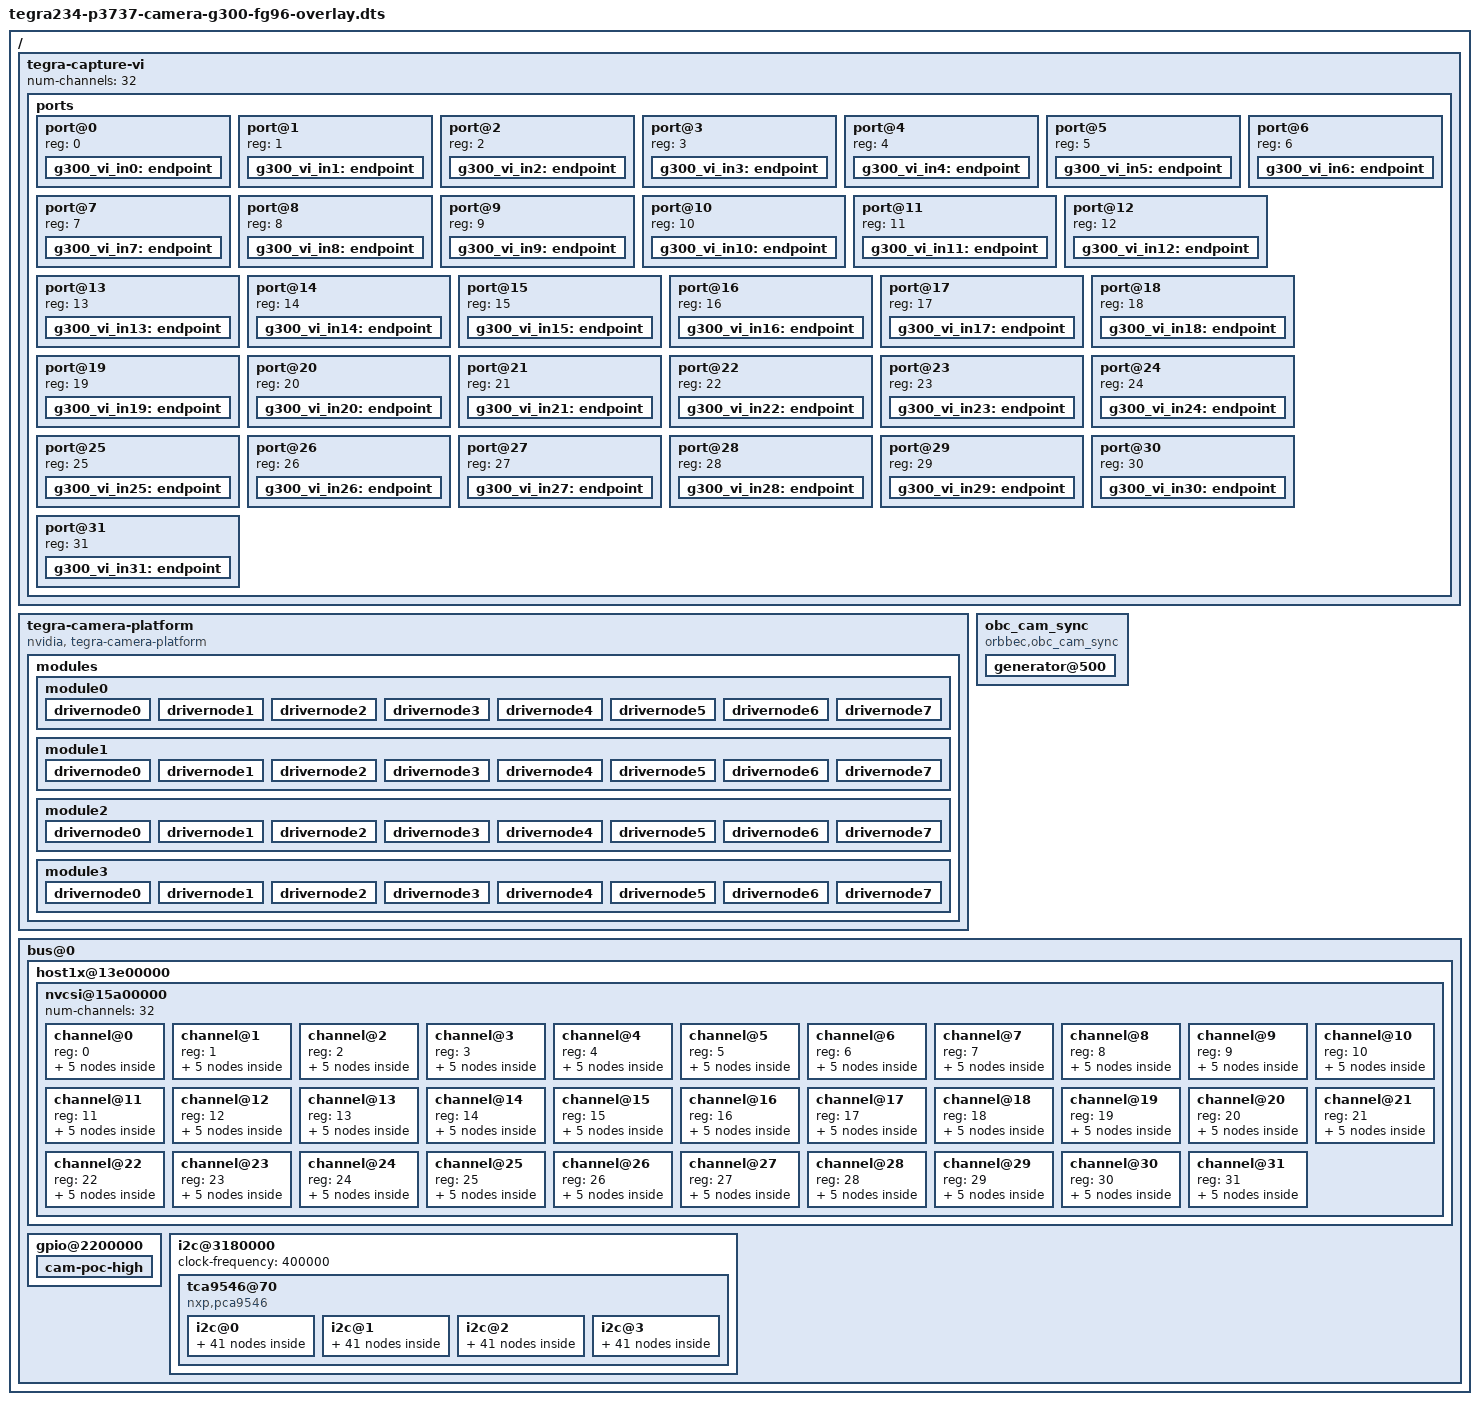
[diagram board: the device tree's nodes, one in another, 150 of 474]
// SPDX-License-Identifier: GPL-2.0-only
// SPDX-FileCopyrightText: Copyright (c) 2024-2029, ORBBEC CORPORATION.  All rights reserved.

/dts-v1/;
/plugin/;

#include <dt-bindings/clock/tegra234-clock.h>
#include <dt-bindings/gpio/tegra234-gpio.h>
#include <dt-bindings/tegra234-p3737-0000+p3701-0000.h>
#include <dt-bindings/pinctrl/pinctrl-tegra.h> 

#define CAM0_PWDN	TEGRA234_MAIN_GPIO(H, 6)  //Pin93 --- UART4_CTS L49/397 - MAX9296_1 PWDN
#define CAM1_PWDN	TEGRA234_MAIN_GPIO(H, 3)  //Pin95 --- UART4_TX L5/394 - MAX9296_2 PWDN
#define CAM2_PWDN	TEGRA234_MAIN_GPIO(AC, 0) //Pin90 --- GPIO15 F10/486 - MAX9296_3 PWDN
#define CAM3_PWDN	TEGRA234_MAIN_GPIO(AC, 1) //Pin92 --- GPIO16 E9/487 - MAX9296_4 PWDN
#define CAM12V_POC	TEGRA234_MAIN_GPIO(AC, 7) //Pin119 --- GPIO12 E10 CAM_VDD_SYS_EN/493 Low enable
#define CAM_SYNCALL	TEGRA234_AON_GPIO(CC, 0)  //E61/SPI2_CLK CAM_INT1/328 -- MAX9296x4 MFP6

#define SYNC_IN    TEGRA234_AON_GPIO(BB, 0) //(BB, 0)

#define PPS_TRIGGER  TEGRA234_AON_GPIO(BB, 2)//(BB, 2)

#define CAMERA_I2C_MUX_BUS(x) (0x1E + x)

/* camera control gpio definitions */
/ {
	overlay-name = "Jetson Orbbec Camera G335Lg";
    jetson-header-name = "Jetson AGX CSI Connector";
    compatible = JETSON_COMPATIBLE;

	fragment@0 {
		target-path = "/";
		__overlay__ {
			tegra-capture-vi {
				num-channels = <32>;
				ports {
					status = "okay";
					#address-cells = <1>;
					#size-cells = <0>;
					port@0 {
						reg = <0>;
						status = "okay";
						g300_vi_in0: endpoint {
							status = "okay";
							vc-id = <0>;
							port-index = <0>; //0
							bus-width = <4>;
							remote-endpoint = <&g300_csi_out0>;
						};
					};
					port@1 {
						reg = <1>;
						status = "okay";
						g300_vi_in1: endpoint {
							status = "okay";
							vc-id = <1>;
							port-index = <0>; //0
							bus-width = <4>;
							remote-endpoint = <&g300_csi_out1>;
						};
					};
					port@2 {
						reg = <2>;
						status = "okay";
						g300_vi_in2: endpoint {
							status = "okay";
							vc-id = <2>;
							port-index = <0>; //0
							bus-width = <4>;
							remote-endpoint = <&g300_csi_out2>;
						};
					};
					port@3 {
						reg = <3>;
						status = "okay";
						g300_vi_in3: endpoint {
							status = "okay";
							vc-id = <3>;
							port-index = <0>; //0
							bus-width = <4>;
							remote-endpoint = <&g300_csi_out3>;
						};
					};

					port@4 {
						reg = <4>;
						status = "okay";
						g300_vi_in4: endpoint {
							status = "okay";
							vc-id = <3>;
							port-index = <0>; //1
							bus-width = <4>;
							remote-endpoint = <&g300_csi_out4>;
						};
					};
					port@5 {
						reg = <5>;
						status = "okay";
						g300_vi_in5: endpoint {
							status = "okay";
							vc-id = <2>;
							port-index = <0>; //1
							bus-width = <4>;
							remote-endpoint = <&g300_csi_out5>;
						};
					};
					port@6 {
						reg = <6>;
						status = "okay";
						g300_vi_in6: endpoint {
							status = "okay";
							vc-id = <1>;
							port-index = <0>; //1
							bus-width = <4>;
							remote-endpoint = <&g300_csi_out6>;
						};
					};
					port@7 {
						reg = <7>;
						status = "okay";
						g300_vi_in7: endpoint {
							status = "okay";
							vc-id = <0>;
							port-index = <0>; //1
							bus-width = <4>;
							remote-endpoint = <&g300_csi_out7>;
						};
					};

					port@8 {
						reg = <8>;
						status = "okay";
						g300_vi_in8: endpoint {
							status = "okay";
							vc-id = <0>;
							port-index = <2>; //2
							bus-width = <4>;
							remote-endpoint = <&g300_csi_out8>;
						};
					};
					port@9 {
						reg = <9>;
						status = "okay";
						g300_vi_in9: endpoint {
							status = "okay";
							vc-id = <1>;
							port-index = <2>; //2
							bus-width = <4>;
							remote-endpoint = <&g300_csi_out9>;
						};
					};
					port@10 {
						reg = <10>;
						status = "okay";
						g300_vi_in10: endpoint {
							status = "okay";
							vc-id = <2>;
							port-index = <2>; //2
							bus-width = <4>;
							remote-endpoint = <&g300_csi_out10>;
						};
					};
					port@11 {
						reg = <11>;
						status = "okay";
						g300_vi_in11: endpoint {
							status = "okay";
							vc-id = <3>;
							port-index = <2>; //2
							bus-width = <4>;
							remote-endpoint = <&g300_csi_out11>;
						};
					};

					port@12 {
						reg = <12>;
						status = "okay";
						g300_vi_in12: endpoint {
							status = "okay";
							vc-id = <3>;
							port-index = <2>; //3
							bus-width = <4>;
							remote-endpoint = <&g300_csi_out12>;
						};
					};
					port@13 {
						reg = <13>;
						status = "okay";
						g300_vi_in13: endpoint {
							status = "okay";
							vc-id = <2>;
							port-index = <2>; //3
							bus-width = <4>;
							remote-endpoint = <&g300_csi_out13>;
						};
					};
					port@14 {
						reg = <14>;
						status = "okay";
						g300_vi_in14: endpoint {
							status = "okay";
							vc-id = <1>;
							port-index = <2>; //3
							bus-width = <4>;
							remote-endpoint = <&g300_csi_out14>;
						};
					};
					port@15 {
						reg = <15>;
						status = "okay";
						g300_vi_in15: endpoint {
							status = "okay";
							vc-id = <0>;
							port-index = <2>; //3
							bus-width = <4>;
							remote-endpoint = <&g300_csi_out15>;
						};
					};

					port@16 {
						reg = <16>;
						status = "okay";
						g300_vi_in16: endpoint {
							status = "okay";
							vc-id = <0>;
							port-index = <4>; //0
							bus-width = <4>;
							remote-endpoint = <&g300_csi_out16>;
						};
					};
					port@17 {
						reg = <17>;
						status = "okay";
						g300_vi_in17: endpoint {
							status = "okay";
							vc-id = <1>;
							port-index = <4>; //0
							bus-width = <4>;
							remote-endpoint = <&g300_csi_out17>;
						};
					};
					port@18 {
						reg = <18>;
						status = "okay";
						g300_vi_in18: endpoint {
							status = "okay";
							vc-id = <2>;
							port-index = <4>; //0
							bus-width = <4>;
							remote-endpoint = <&g300_csi_out18>;
						};
					};
					port@19 {
						reg = <19>;
						status = "okay";
						g300_vi_in19: endpoint {
							status = "okay";
							vc-id = <3>;
							port-index = <4>; //0
							bus-width = <4>;
							remote-endpoint = <&g300_csi_out19>;
						};
					};

					port@20 {
						reg = <20>;
						status = "okay";
						g300_vi_in20: endpoint {
							status = "okay";
							vc-id = <3>;
							port-index = <4>; //1
							bus-width = <4>;
							remote-endpoint = <&g300_csi_out20>;
						};
					};
					port@21 {
						reg = <21>;
						status = "okay";
						g300_vi_in21: endpoint {
							status = "okay";
							vc-id = <2>;
							port-index = <4>; //1
							bus-width = <4>;
							remote-endpoint = <&g300_csi_out21>;
						};
					};
					port@22 {
						reg = <22>;
						status = "okay";
						g300_vi_in22: endpoint {
							status = "okay";
							vc-id = <1>;
							port-index = <4>; //1
							bus-width = <4>;
							remote-endpoint = <&g300_csi_out22>;
						};
					};
					port@23 {
						reg = <23>;
						status = "okay";
						g300_vi_in23: endpoint {
							status = "okay";
							vc-id = <0>;
							port-index = <4>; //1
							bus-width = <4>;
							remote-endpoint = <&g300_csi_out23>;
						};
					};

					port@24 {
						reg = <24>;
						status = "okay";
						g300_vi_in24: endpoint {
							status = "okay";
							vc-id = <0>;
							port-index = <5>; //2
							bus-width = <4>;
							remote-endpoint = <&g300_csi_out24>;
						};
					};
					port@25 {
						reg = <25>;
						status = "okay";
						g300_vi_in25: endpoint {
							status = "okay";
							vc-id = <1>;
							port-index = <5>; //2
							bus-width = <4>;
							remote-endpoint = <&g300_csi_out25>;
						};
					};
					port@26 {
						reg = <26>;
						status = "okay";
						g300_vi_in26: endpoint {
							status = "okay";
							vc-id = <2>;
							port-index = <5>; //2
							bus-width = <4>;
							remote-endpoint = <&g300_csi_out26>;
						};
					};
					port@27 {
						reg = <27>;
						status = "okay";
						g300_vi_in27: endpoint {
							status = "okay";
							vc-id = <3>;
							port-index = <5>; //2
							bus-width = <4>;
							remote-endpoint = <&g300_csi_out27>;
						};
					};

					port@28 {
						reg = <28>;
						status = "okay";
						g300_vi_in28: endpoint {
							status = "okay";
							vc-id = <3>;
							port-index = <5>; //3
							bus-width = <4>;
							remote-endpoint = <&g300_csi_out28>;
						};
					};
					port@29 {
						reg = <29>;
						status = "okay";
						g300_vi_in29: endpoint {
							status = "okay";
							vc-id = <2>;
							port-index = <5>; //3
							bus-width = <4>;
							remote-endpoint = <&g300_csi_out29>;
						};
					};
					port@30 {
						reg = <30>;
						status = "okay";
						g300_vi_in30: endpoint {
							status = "okay";
							vc-id = <1>;
							port-index = <5>; //3
							bus-width = <4>;
							remote-endpoint = <&g300_csi_out30>;
						};
					};
					port@31 {
						reg = <31>;
						status = "okay";
						g300_vi_in31: endpoint {
							status = "okay";
							vc-id = <0>;
							port-index = <5>; //3
							bus-width = <4>;
							remote-endpoint = <&g300_csi_out31>;
						};
					};
				};
			};
			tegra-camera-platform {
				compatible = "nvidia, tegra-camera-platform";
				num_csi_lanes = <16>;
				max_lane_speed = <1500000>;
				min_bits_per_pixel = <8>;
				vi_peak_byte_per_pixel = <2>;
				vi_bw_margin_pct = <25>;
				max_pixel_rate = <750000>;
				isp_peak_byte_per_pixel = <5>;
				isp_bw_margin_pct = <25>;
				status = "okay";

				modules {
					status = "okay";
					module0 {
						status = "okay";
						badge = "g300_0";
						position = "topleft";
						orientation = "1";
						drivernode0 {
							status = "okay";
							/* Declare PCL support driver (classically known as guid)  */
							pcl_id = "v4l2_sensor";
							/* Declare the device-tree hierarchy to driver instance */
							sysfs-device-tree = "/sys/firmware/devicetree/base/bus@0/i2c@3180000/tca9546@70/i2c@0/g2m0@66";
						};

						drivernode1 {
							status = "okay";
							/* Declare PCL support driver (classically known as guid)  */
							pcl_id = "v4l2_sensor";
							/* Declare the device-tree hierarchy to driver instance */
							sysfs-device-tree = "/sys/firmware/devicetree/base/bus@0/i2c@3180000/tca9546@70/i2c@0/g2m1@67";
						};

						drivernode2 {
							status = "okay";
							/* Declare PCL support driver (classically known as guid)  */
							pcl_id = "v4l2_sensor";
							/* Declare the device-tree hierarchy to driver instance */
							sysfs-device-tree = "/sys/firmware/devicetree/base/bus@0/i2c@3180000/tca9546@70/i2c@0/g2m2@68";
						};

						drivernode3 {
							status = "okay";
							/* Declare PCL support driver (classically known as guid)  */
							pcl_id = "v4l2_sensor";
							/* Declare the device-tree hierarchy to driver instance */
							sysfs-device-tree = "/sys/firmware/devicetree/base/bus@0/i2c@3180000/tca9546@70/i2c@0/g2m3@69";
						};

						drivernode4 {
							status = "okay";
							/* Declare PCL support driver (classically known as guid)  */
							pcl_id = "v4l2_sensor";
							/* Declare the device-tree hierarchy to driver instance */
							sysfs-device-tree = "/sys/firmware/devicetree/base/bus@0/i2c@3180000/tca9546@70/i2c@0/g2m0@6A";
						};

						drivernode5 {
							status = "okay";
							/* Declare PCL support driver (classically known as guid)  */
							pcl_id = "v4l2_sensor";
							/* Declare the device-tree hierarchy to driver instance */
							sysfs-device-tree = "/sys/firmware/devicetree/base/bus@0/i2c@3180000/tca9546@70/i2c@0/g2m1@6B";
						};

						drivernode6 {
							status = "okay";
							/* Declare PCL support driver (classically known as guid)  */
							pcl_id = "v4l2_sensor";
							/* Declare the device-tree hierarchy to driver instance */
							sysfs-device-tree = "/sys/firmware/devicetree/base/bus@0/i2c@3180000/tca9546@70/i2c@0/g2m2@6C";
						};

						drivernode7 {
							status = "okay";
							/* Declare PCL support driver (classically known as guid)  */
							pcl_id = "v4l2_sensor";
							/* Declare the device-tree hierarchy to driver instance */
							sysfs-device-tree = "/sys/firmware/devicetree/base/bus@0/i2c@3180000/tca9546@70/i2c@0/g2m3@6D";
						};
					};
					module1 {
						status = "okay";
						badge = "g300_1";
						position = "topright";
						orientation = "1";

						drivernode0 {
							status = "okay";
							/* Declare PCL support driver (classically known as guid)  */
							pcl_id = "v4l2_sensor";
							sysfs-device-tree = "/sys/firmware/devicetree/base/bus@0/i2c@3180000/tca9546@70/i2c@1/g2m0@66";
						};

						drivernode1 {
							status = "okay";
							/* Declare PCL support driver (classically known as guid)  */
							pcl_id = "v4l2_sensor";
							/* Declare the device-tree hierarchy to driver instance */
							sysfs-device-tree = "/sys/firmware/devicetree/base/bus@0/i2c@3180000/tca9546@70/i2c@1/g2m1@67";
						};

						drivernode2 {
							status = "okay";
							/* Declare PCL support driver (classically known as guid)  */
							pcl_id = "v4l2_sensor";
							/* Declare the device-tree hierarchy to driver instance */
							sysfs-device-tree = "/sys/firmware/devicetree/base/bus@0/i2c@3180000/tca9546@70/i2c@1/g2m2@68";
						};

						drivernode3 {
							status = "okay";
							/* Declare PCL support driver (classically known as guid)  */
							pcl_id = "v4l2_sensor";
							/* Declare the device-tree hierarchy to driver instance */
							sysfs-device-tree = "/sys/firmware/devicetree/base/bus@0/i2c@3180000/tca9546@70/i2c@1/g2m3@69";
						};

						drivernode4 {
							status = "okay";
								/* Declare PCL support driver (classically known as guid)  */
							pcl_id = "v4l2_sensor";
							/* Declare the device-tree hierarchy to driver instance */
							sysfs-device-tree = "/sys/firmware/devicetree/base/bus@0/i2c@3180000/tca9546@70/i2c@1/g2m0@6A";
						};

						drivernode5 {
							status = "okay";
							/* Declare PCL support driver (classically known as guid)  */
							pcl_id = "v4l2_sensor";
							/* Declare the device-tree hierarchy to driver instance */
							sysfs-device-tree = "/sys/firmware/devicetree/base/bus@0/i2c@3180000/tca9546@70/i2c@1/g2m1@6B";
						};

						drivernode6 {
							status = "okay";
							/* Declare PCL support driver (classically known as guid)  */
							pcl_id = "v4l2_sensor";
							/* Declare the device-tree hierarchy to driver instance */
							sysfs-device-tree = "/sys/firmware/devicetree/base/bus@0/i2c@3180000/tca9546@70/i2c@1/g2m2@6C";
						};

						drivernode7 {
							status = "okay";
							/* Declare PCL support driver (classically known as guid)  */
							pcl_id = "v4l2_sensor";
							/* Declare the device-tree hierarchy to driver instance */
							sysfs-device-tree = "/sys/firmware/devicetree/base/bus@0/i2c@3180000/tca9546@70/i2c@1/g2m3@6D";
						};
					};

					module2 {
						status = "okay";
						badge = "g300_2";
						position = "bottomleft";
						orientation = "1";

						drivernode0 {
							status = "okay";
							/* Declare PCL support driver (classically known as guid)  */
							pcl_id = "v4l2_sensor";
							sysfs-device-tree = "/sys/firmware/devicetree/base/bus@0/i2c@3180000/tca9546@70/i2c@2/g2m0@66";
						};

						drivernode1 {
							status = "okay";
							/* Declare PCL support driver (classically known as guid)  */
							pcl_id = "v4l2_sensor";
							/* Declare the device-tree hierarchy to driver instance */
							sysfs-device-tree = "/sys/firmware/devicetree/base/bus@0/i2c@3180000/tca9546@70/i2c@2/g2m1@67";
						};

						drivernode2 {
							status = "okay";
							/* Declare PCL support driver (classically known as guid)  */
							pcl_id = "v4l2_sensor";
							/* Declare the device-tree hierarchy to driver instance */
							sysfs-device-tree = "/sys/firmware/devicetree/base/bus@0/i2c@3180000/tca9546@70/i2c@2/g2m2@68";
						};

						drivernode3 {
							status = "okay";
							/* Declare PCL support driver (classically known as guid)  */
							pcl_id = "v4l2_sensor";
							/* Declare the device-tree hierarchy to driver instance */
							sysfs-device-tree = "/sys/firmware/devicetree/base/bus@0/i2c@3180000/tca9546@70/i2c@2/g2m3@69";
						};

						drivernode4 {
							status = "okay";
								/* Declare PCL support driver (classically known as guid)  */
							pcl_id = "v4l2_sensor";
							/* Declare the device-tree hierarchy to driver instance */
							sysfs-device-tree = "/sys/firmware/devicetree/base/bus@0/i2c@3180000/tca9546@70/i2c@2/g2m0@6A";
						};

						drivernode5 {
							status = "okay";
							/* Declare PCL support driver (classically known as guid)  */
							pcl_id = "v4l2_sensor";
							/* Declare the device-tree hierarchy to driver instance */
							sysfs-device-tree = "/sys/firmware/devicetree/base/bus@0/i2c@3180000/tca9546@70/i2c@2/g2m1@6B";
						};

						drivernode6 {
							status = "okay";
							/* Declare PCL support driver (classically known as guid)  */
							pcl_id = "v4l2_sensor";
							/* Declare the device-tree hierarchy to driver instance */
							sysfs-device-tree = "/sys/firmware/devicetree/base/bus@0/i2c@3180000/tca9546@70/i2c@2/g2m2@6C";
						};

						drivernode7 {
							status = "okay";
							/* Declare PCL support driver (classically known as guid)  */
							pcl_id = "v4l2_sensor";
							/* Declare the device-tree hierarchy to driver instance */
							sysfs-device-tree = "/sys/firmware/devicetree/base/bus@0/i2c@3180000/tca9546@70/i2c@2/g2m3@6D";
						};
					};
					module3 {
						status = "okay";
						badge = "g300_3";
						position = "bottomright";
						orientation = "1";

						drivernode0 {
							status = "okay";
							/* Declare PCL support driver (classically known as guid)  */
							pcl_id = "v4l2_sensor";
							sysfs-device-tree = "/sys/firmware/devicetree/base/bus@0/i2c@3180000/tca9546@70/i2c@3/g2m0@66";
						};

						drivernode1 {
							status = "okay";
							/* Declare PCL support driver (classically known as guid)  */
							pcl_id = "v4l2_sensor";
							/* Declare the device-tree hierarchy to driver instance */
							sysfs-device-tree = "/sys/firmware/devicetree/base/bus@0/i2c@3180000/tca9546@70/i2c@3/g2m1@67";
						};

						drivernode2 {
							status = "okay";
							/* Declare PCL support driver (classically known as guid)  */
							pcl_id = "v4l2_sensor";
							/* Declare the device-tree hierarchy to driver instance */
							sysfs-device-tree = "/sys/firmware/devicetree/base/bus@0/i2c@3180000/tca9546@70/i2c@3/g2m2@68";
						};

						drivernode3 {
							status = "okay";
							/* Declare PCL support driver (classically known as guid)  */
							pcl_id = "v4l2_sensor";
							/* Declare the device-tree hierarchy to driver instance */
							sysfs-device-tree = "/sys/firmware/devicetree/base/bus@0/i2c@3180000/tca9546@70/i2c@3/g2m3@69";
						};

						drivernode4 {
							status = "okay";
								/* Declare PCL support driver (classically known as guid)  */
							pcl_id = "v4l2_sensor";
							/* Declare the device-tree hierarchy to driver instance */
							sysfs-device-tree = "/sys/firmware/devicetree/base/bus@0/i2c@3180000/tca9546@70/i2c@3/g2m0@6A";
						};

						drivernode5 {
							status = "okay";
							/* Declare PCL support driver (classically known as guid)  */
							pcl_id = "v4l2_sensor";
							/* Declare the device-tree hierarchy to driver instance */
							sysfs-device-tree = "/sys/firmware/devicetree/base/bus@0/i2c@3180000/tca9546@70/i2c@3/g2m1@6B";
						};

						drivernode6 {
							status = "okay";
							/* Declare PCL support driver (classically known as guid)  */
							pcl_id = "v4l2_sensor";
							/* Declare the device-tree hierarchy to driver instance */
							sysfs-device-tree = "/sys/firmware/devicetree/base/bus@0/i2c@3180000/tca9546@70/i2c@3/g2m2@6C";
						};

						drivernode7 {
							status = "okay";
							/* Declare PCL support driver (classically known as guid)  */
							pcl_id = "v4l2_sensor";
							/* Declare the device-tree hierarchy to driver instance */
							sysfs-device-tree = "/sys/firmware/devicetree/base/bus@0/i2c@3180000/tca9546@70/i2c@3/g2m3@6D";
						};
					};
				};
			};

			obc_cam_sync {
				compatible = "orbbec,obc_cam_sync";
				ranges = <0x0 0x0 0xc6a0000 0x10000>;
				reg = <0x0 0xc6a0000 0x0 0x18>;
				#address-cells = <1>;
				#size-cells = <1>;
				status = "okay";
				//sync-in-gpios = <&gpio_aon SYNC_IN GPIO_ACTIVE_HIGH>;
				//sync-out-gpios = <&gpio_aon CAM_SYNCALL GPIO_ACTIVE_HIGH>;  //Use hrtimer to generate trigger signals
				pwms = <&pwm8 0 33333333>; //Use PWM to generate trigger signals, Default PWM mode, if use hrtimer comment out this line
				/* EDGE_OUT #3 */
				generator@500 {
					reg = <0x500 0x80>;
					freq_hz = <30>;
					duty_cycle = <10>;
					offset_ms = <0>;
					status = "okay";
				};
			};

			bus@0 {
				host1x@13e00000 {
					nvcsi@15a00000 {
						#address-cells = <1>;
						#size-cells = <0>;

						num-channels = <32>;

						channel@0 {
							reg = <0>;
							status = "okay";
							ports {
								status = "okay";
								#address-cells = <1>;
								#size-cells = <0>;
								port@0 {
									reg = <0>;
									status = "okay";
									g300_csi_in0: endpoint@0 {
										status = "okay";
										port-index = <0>; //0
										bus-width = <4>;
										remote-endpoint = <&g2m0_0_out>;
									};
								};
								port@1 {
									reg = <1>;
									status = "okay";
									g300_csi_out0: endpoint@1 {
										status = "okay";
										remote-endpoint = <&g300_vi_in0>;
									};
								};
							};
						};
						channel@1 {
							reg = <1>;
							status = "okay";
							ports {
								status = "okay";
								#address-cells = <1>;
								#size-cells = <0>;
								port@0 {
									reg = <0>;
									status = "okay";
									g300_csi_in1: endpoint@2 {
										status = "okay";
										port-index = <0>; //0
										bus-width = <4>;
										remote-endpoint = <&g2m0_1_out>;
									};
								};
								port@1 {
									reg = <1>;
									status = "okay";
									g300_csi_out1: endpoint@3 {
										status = "okay";
										remote-endpoint = <&g300_vi_in1>;
									};
								};
							};
						};
						channel@2 {
							reg = <2>;
							status = "okay";
							ports {
								status = "okay";
								#address-cells = <1>;
								#size-cells = <0>;
								port@0 {
									reg = <0>;
									status = "okay";
									g300_csi_in2: endpoint@4 {
										status = "okay";
										port-index = <0>; //0
										bus-width = <4>;
										remote-endpoint = <&g2m0_2_out>;
									};
								};
								port@1 {
									reg = <1>;
									status = "okay";
									g300_csi_out2: endpoint@5 {
										status = "okay";
										remote-endpoint = <&g300_vi_in2>;
									};
								};
							};
						};
						channel@3 {
							reg = <3>;
							status = "okay";
							ports {
								status = "okay";
								#address-cells = <1>;
								#size-cells = <0>;
								port@0 {
									reg = <0>;
									status = "okay";
									g300_csi_in3: endpoint@6 {
										status = "okay";
										port-index = <0>; //0
										bus-width = <4>;
										remote-endpoint = <&g2m0_3_out>;
									};
								};
								port@1 {
									reg = <1>;
									status = "okay";
									g300_csi_out3: endpoint@7 {
										status = "okay";
										remote-endpoint = <&g300_vi_in3>;
									};
								};
							};
						};

						channel@4 {
							reg = <4>;
							status = "okay";
							ports {
								status = "okay";
								#address-cells = <1>;
								#size-cells = <0>;
								port@0 {
									reg = <0>;
									status = "okay";
									g300_csi_in4: endpoint@8 {
										status = "okay";
										port-index = <0>; //1
										bus-width = <4>;
										remote-endpoint = <&g2m1_0_out>;
									};
								};
								port@1 {
									reg = <1>;
									status = "okay";
									g300_csi_out4: endpoint@9 {
										status = "okay";
										remote-endpoint = <&g300_vi_in4>;
									};
								};
							};
						};
						channel@5 {
							reg = <5>;
							status = "okay";
							ports {
								status = "okay";
								#address-cells = <1>;
								#size-cells = <0>;
								port@0 {
									reg = <0>;
									status = "okay";
									g300_csi_in5: endpoint@10 {
										status = "okay";
										port-index = <0>; //1
										bus-width = <4>;
										remote-endpoint = <&g2m1_1_out>;
									};
								};
								port@1 {
									reg = <1>;
									status = "okay";
									g300_csi_out5: endpoint@11 {
										status = "okay";
										remote-endpoint = <&g300_vi_in5>;
									};
								};
							};
						};
						channel@6 {
							reg = <6>;
							status = "okay";
							ports {
								status = "okay";
								#address-cells = <1>;
								#size-cells = <0>;
								port@0 {
									reg = <0>;
									status = "okay";
									g300_csi_in6: endpoint@12 {
										status = "okay";
										port-index = <0>; //1
										bus-width = <4>;
										remote-endpoint = <&g2m1_2_out>;
									};
								};
								port@1 {
									reg = <1>;
									status = "okay";
									g300_csi_out6: endpoint@13 {
										status = "okay";
										remote-endpoint = <&g300_vi_in6>;
									};
								};
							};
						};
						channel@7 {
							reg = <7>;
							status = "okay";
							ports {
								status = "okay";
								#address-cells = <1>;
								#size-cells = <0>;
								port@0 {
									reg = <0>;
									status = "okay";
									g300_csi_in7: endpoint@14 {
										status = "okay";
										port-index = <0>; //1
										bus-width = <4>;
										remote-endpoint = <&g2m1_3_out>;
									};
								};
								port@1 {
									reg = <1>;
									status = "okay";
									g300_csi_out7: endpoint@15 {
										status = "okay";
										remote-endpoint = <&g300_vi_in7>;
									};
								};
							};
						};

						channel@8 {
							reg = <8>;
							status = "okay";
							ports {
								status = "okay";
								#address-cells = <1>;
								#size-cells = <0>;
								port@0 {
									reg = <0>;
									status = "okay";
									g300_csi_in8: endpoint@16 {
										status = "okay";
										port-index = <2>; //2
										bus-width = <4>;
										remote-endpoint = <&g2m2_0_out>;
									};
								};
								port@1 {
									reg = <1>;
									status = "okay";
									g300_csi_out8: endpoint@17 {
										status = "okay";
										remote-endpoint = <&g300_vi_in8>;
									};
								};
							};
						};
						channel@9 {
							reg = <9>;
							status = "okay";
							ports {
								status = "okay";
								#address-cells = <1>;
								#size-cells = <0>;
								port@0 {
									reg = <0>;
									status = "okay";
									g300_csi_in9: endpoint@18 {
										status = "okay";
										port-index = <2>; //2
										bus-width = <4>;
										remote-endpoint = <&g2m2_1_out>;
									};
								};
								port@1 {
									reg = <1>;
									status = "okay";
									g300_csi_out9: endpoint@19 {
										status = "okay";
										remote-endpoint = <&g300_vi_in9>;
									};
								};
							};
						};
						channel@10 {
							reg = <10>;
							status = "okay";
							ports {
								status = "okay";
								#address-cells = <1>;
								#size-cells = <0>;
								port@0 {
									reg = <0>;
									status = "okay";
									g300_csi_in10: endpoint@20 {
										status = "okay";
										port-index = <2>; //2
										bus-width = <4>;
										remote-endpoint = <&g2m2_2_out>;
									};
								};
								port@1 {
									reg = <1>;
									status = "okay";
									g300_csi_out10: endpoint@21 {
										status = "okay";
										remote-endpoint = <&g300_vi_in10>;
									};
								};
							};
						};
						channel@11 {
							reg = <11>;
							status = "okay";
							ports {
								status = "okay";
								#address-cells = <1>;
								#size-cells = <0>;
								port@0 {
									reg = <0>;
									status = "okay";
									g300_csi_in11: endpoint@22 {
										status = "okay";
										port-index = <2>; //2
										bus-width = <4>;
										remote-endpoint = <&g2m2_3_out>;
									};
								};
								port@1 {
									reg = <1>;
									status = "okay";
									g300_csi_out11: endpoint@23 {
										status = "okay";
										remote-endpoint = <&g300_vi_in11>;
									};
								};
							};
						};

						channel@12 {
							reg = <12>;
							status = "okay";
							ports {
								status = "okay";
								#address-cells = <1>;
								#size-cells = <0>;
								port@0 {
									reg = <0>;
									status = "okay";
									g300_csi_in12: endpoint@24 {
										status = "okay";
										port-index = <2>; //3
										bus-width = <4>;
										remote-endpoint = <&g2m3_0_out>;
									};
								};
								port@1 {
									reg = <1>;
									status = "okay";
									g300_csi_out12: endpoint@25 {
										status = "okay";
										remote-endpoint = <&g300_vi_in12>;
									};
								};
							};
						};
						channel@13 {
							reg = <13>;
							status = "okay";
							ports {
								status = "okay";
								#address-cells = <1>;
								#size-cells = <0>;
								port@0 {
									reg = <0>;
									status = "okay";
									g300_csi_in13: endpoint@26 {
										status = "okay";
										port-index = <2>; //3
										bus-width = <4>;
										remote-endpoint = <&g2m3_1_out>;
									};
								};
								port@1 {
									reg = <1>;
									status = "okay";
									g300_csi_out13: endpoint@27 {
										status = "okay";
										remote-endpoint = <&g300_vi_in13>;
									};
								};
							};
						};
						channel@14 {
							reg = <14>;
							status = "okay";
							ports {
								status = "okay";
								#address-cells = <1>;
								#size-cells = <0>;
								port@0 {
									reg = <0>;
									status = "okay";
									g300_csi_in14: endpoint@28 {
										status = "okay";
										port-index = <2>; //3
										bus-width = <4>;
										remote-endpoint = <&g2m3_2_out>;
									};
								};
								port@1 {
									reg = <1>;
									status = "okay";
									g300_csi_out14: endpoint@29 {
										status = "okay";
										remote-endpoint = <&g300_vi_in14>;
									};
								};
							};
						};
						channel@15 {
							reg = <15>;
							status = "okay";
							ports {
								status = "okay";
								#address-cells = <1>;
								#size-cells = <0>;
								port@0 {
									reg = <0>;
									status = "okay";
									g300_csi_in15: endpoint@30 {
										status = "okay";
										port-index = <2>; //3
										bus-width = <4>;
										remote-endpoint = <&g2m3_3_out>;
									};
								};
								port@1 {
									reg = <1>;
									status = "okay";
									g300_csi_out15: endpoint@31 {
										status = "okay";
										remote-endpoint = <&g300_vi_in15>;
									};
								};
							};
						};

						channel@16 {
							reg = <16>;
							status = "okay";
							ports {
								status = "okay";
								#address-cells = <1>;
								#size-cells = <0>;
								port@0 {
									reg = <0>;
									status = "okay";
									g300_csi_in16: endpoint@32 {
										status = "okay";
										port-index = <4>; //0
										bus-width = <4>;
										remote-endpoint = <&g2m4_0_out>;
									};
								};
								port@1 {
									reg = <1>;
									status = "okay";
									g300_csi_out16: endpoint@33 {
										status = "okay";
										remote-endpoint = <&g300_vi_in16>;
									};
								};
							};
						};
						channel@17 {
							reg = <17>;
							status = "okay";
							ports {
								status = "okay";
								#address-cells = <1>;
								#size-cells = <0>;
								port@0 {
									reg = <0>;
									status = "okay";
									g300_csi_in17: endpoint@34 {
										status = "okay";
										port-index = <4>; //0
										bus-width = <4>;
										remote-endpoint = <&g2m4_1_out>;
									};
								};
								port@1 {
									reg = <1>;
									status = "okay";
									g300_csi_out17: endpoint@35 {
										status = "okay";
										remote-endpoint = <&g300_vi_in17>;
									};
								};
							};
						};
						channel@18 {
							reg = <18>;
							status = "okay";
							ports {
								status = "okay";
								#address-cells = <1>;
								#size-cells = <0>;
								port@0 {
									reg = <0>;
									status = "okay";
									g300_csi_in18: endpoint@36 {
										status = "okay";
										port-index = <4>; //0
										bus-width = <4>;
										remote-endpoint = <&g2m4_2_out>;
									};
								};
								port@1 {
									reg = <1>;
									status = "okay";
									g300_csi_out18: endpoint@37 {
										status = "okay";
										remote-endpoint = <&g300_vi_in18>;
									};
								};
							};
						};
						channel@19 {
							reg = <19>;
							status = "okay";
							ports {
								status = "okay";
								#address-cells = <1>;
								#size-cells = <0>;
								port@0 {
									reg = <0>;
									status = "okay";
									g300_csi_in19: endpoint@38 {
										status = "okay";
										port-index = <4>; //0
										bus-width = <4>;
										remote-endpoint = <&g2m4_3_out>;
									};
								};
								port@1 {
									reg = <1>;
									status = "okay";
									g300_csi_out19: endpoint@39 {
										status = "okay";
										remote-endpoint = <&g300_vi_in19>;
									};
								};
							};
						};

						channel@20 {
							reg = <20>;
							status = "okay";
							ports {
								status = "okay";
								#address-cells = <1>;
								#size-cells = <0>;
								port@0 {
									reg = <0>;
									status = "okay";
									g300_csi_in20: endpoint@40 {
										status = "okay";
										port-index = <4>; //1
										bus-width = <4>;
										remote-endpoint = <&g2m5_0_out>;
									};
								};
								port@1 {
									reg = <1>;
									status = "okay";
									g300_csi_out20: endpoint@41 {
										status = "okay";
										remote-endpoint = <&g300_vi_in20>;
									};
								};
							};
						};
						channel@21 {
							reg = <21>;
							status = "okay";
							ports {
								status = "okay";
								#address-cells = <1>;
								#size-cells = <0>;
								port@0 {
									reg = <0>;
									status = "okay";
									g300_csi_in21: endpoint@42 {
										status = "okay";
										port-index = <4>; //1
										bus-width = <4>;
										remote-endpoint = <&g2m5_1_out>;
									};
								};
								port@1 {
									reg = <1>;
									status = "okay";
									g300_csi_out21: endpoint@43 {
										status = "okay";
										remote-endpoint = <&g300_vi_in21>;
									};
								};
							};
						};
						channel@22 {
							reg = <22>;
							status = "okay";
							ports {
								status = "okay";
								#address-cells = <1>;
								#size-cells = <0>;
								port@0 {
									reg = <0>;
									status = "okay";
									g300_csi_in22: endpoint@44 {
										status = "okay";
										port-index = <4>; //1
										bus-width = <4>;
										remote-endpoint = <&g2m5_2_out>;
									};
								};
								port@1 {
									reg = <1>;
									status = "okay";
									g300_csi_out22: endpoint@45 {
										status = "okay";
										remote-endpoint = <&g300_vi_in22>;
									};
								};
							};
						};
						channel@23 {
							reg = <23>;
							status = "okay";
							ports {
								status = "okay";
								#address-cells = <1>;
								#size-cells = <0>;
								port@0 {
									reg = <0>;
									status = "okay";
									g300_csi_in23: endpoint@46 {
										status = "okay";
										port-index = <4>; //1
										bus-width = <4>;
										remote-endpoint = <&g2m5_3_out>;
									};
								};
								port@1 {
									reg = <1>;
									status = "okay";
									g300_csi_out23: endpoint@47 {
										status = "okay";
										remote-endpoint = <&g300_vi_in23>;
									};
								};
							};
						};

						channel@24 {
							reg = <24>;
							status = "okay";
							ports {
								status = "okay";
								#address-cells = <1>;
								#size-cells = <0>;
								port@0 {
									reg = <0>;
									status = "okay";
									g300_csi_in24: endpoint@48 {
										status = "okay";
										port-index = <6>; //2
										bus-width = <4>;
										remote-endpoint = <&g2m6_0_out>;
									};
								};
								port@1 {
									reg = <1>;
									status = "okay";
									g300_csi_out24: endpoint@49 {
										status = "okay";
										remote-endpoint = <&g300_vi_in24>;
									};
								};
							};
						};
						channel@25 {
							reg = <25>;
							status = "okay";
							ports {
								status = "okay";
								#address-cells = <1>;
								#size-cells = <0>;
								port@0 {
									reg = <0>;
									status = "okay";
									g300_csi_in25: endpoint@50 {
										status = "okay";
										port-index = <6>; //2
										bus-width = <4>;
										remote-endpoint = <&g2m6_1_out>;
									};
								};
								port@1 {
									reg = <1>;
									status = "okay";
									g300_csi_out25: endpoint@51 {
										status = "okay";
										remote-endpoint = <&g300_vi_in25>;
									};
								};
							};
						};
						channel@26 {
							reg = <26>;
							status = "okay";
							ports {
								status = "okay";
								#address-cells = <1>;
								#size-cells = <0>;
								port@0 {
									reg = <0>;
									status = "okay";
									g300_csi_in26: endpoint@52 {
										status = "okay";
										port-index = <6>; //2
										bus-width = <4>;
										remote-endpoint = <&g2m6_2_out>;
									};
								};
								port@1 {
									reg = <1>;
									status = "okay";
									g300_csi_out26: endpoint@53 {
										status = "okay";
										remote-endpoint = <&g300_vi_in26>;
									};
								};
							};
						};
						channel@27 {
							reg = <27>;
							status = "okay";
							ports {
								status = "okay";
								#address-cells = <1>;
								#size-cells = <0>;
								port@0 {
									reg = <0>;
									status = "okay";
									g300_csi_in27: endpoint@54 {
										status = "okay";
										port-index = <6>; //2
										bus-width = <4>;
										remote-endpoint = <&g2m6_3_out>;
									};
								};
								port@1 {
									reg = <1>;
									status = "okay";
									g300_csi_out27: endpoint@55 {
										status = "okay";
										remote-endpoint = <&g300_vi_in27>;
									};
								};
							};
						};

						channel@28 {
							reg = <28>;
							status = "okay";
							ports {
								status = "okay";
								#address-cells = <1>;
								#size-cells = <0>;
								port@0 {
									reg = <0>;
									status = "okay";
									g300_csi_in28: endpoint@56 {
										status = "okay";
										port-index = <6>; //3
										bus-width = <4>;
										remote-endpoint = <&g2m7_0_out>;
									};
								};
								port@1 {
									reg = <1>;
									status = "okay";
									g300_csi_out28: endpoint@57 {
										status = "okay";
										remote-endpoint = <&g300_vi_in28>;
									};
								};
							};
						};
						channel@29 {
							reg = <29>;
							status = "okay";
							ports {
								status = "okay";
								#address-cells = <1>;
								#size-cells = <0>;
								port@0 {
									reg = <0>;
									status = "okay";
									g300_csi_in29: endpoint@58 {
										status = "okay";
										port-index = <6>; //3
										bus-width = <4>;
										remote-endpoint = <&g2m7_1_out>;
									};
								};
								port@1 {
									reg = <1>;
									status = "okay";
									g300_csi_out29: endpoint@59 {
										status = "okay";
										remote-endpoint = <&g300_vi_in29>;
									};
								};
							};
						};
						channel@30 {
							reg = <30>;
							status = "okay";
							ports {
								status = "okay";
								#address-cells = <1>;
								#size-cells = <0>;
								port@0 {
									reg = <0>;
									status = "okay";
									g300_csi_in30: endpoint@60 {
										status = "okay";
										port-index = <6>; //3
										bus-width = <4>;
										remote-endpoint = <&g2m7_2_out>;
									};
								};
								port@1 {
									reg = <1>;
									status = "okay";
									g300_csi_out30: endpoint@61 {
										status = "okay";
										remote-endpoint = <&g300_vi_in30>;
									};
								};
							};
						};
						channel@31 {
							reg = <31>;
							status = "okay";
							ports {
								status = "okay";
								#address-cells = <1>;
								#size-cells = <0>;
								port@0 {
									reg = <0>;
									status = "okay";
									g300_csi_in31: endpoint@62 {
										status = "okay";
										port-index = <6>; //3
										bus-width = <4>;
										remote-endpoint = <&g2m7_3_out>;
									};
								};
								port@1 {
									reg = <1>;
									status = "okay";
									g300_csi_out31: endpoint@63 {
										status = "okay";
										remote-endpoint = <&g300_vi_in31>;
									};
								};
							};
						};
					};
				};

				gpio@2200000 {
					/*
					camera-control-output-high {
						gpio-hog;
						output-high;
						gpios = <CAM0_PWDN 0 CAM1_PWDN 0 CAM2_RST_L 0 CAM3_RST_L 0>;
						label = "cam0-pwdn", "cam1-pwdn", "cam2-pwdn", "cam3-pwdn";
					};
					*/
					cam-poc-high {
						gpio-hog;
						output-high;
						gpios = <CAM12V_POC 0>;
						label = "cam12-poc";
					};
				};

				i2c@3180000 {
					status = "okay";
					clock-frequency = <400000>;
					tca9546@70 {
						status = "okay";
						reg = <0x70>;
						compatible = "nxp,pca9546";
						#address-cells = <1>;
						#size-cells = <0>;
						skip_mux_detect = "yes";
						vcc-supply = <&vdd_1v8_ls>;
						/*vcc-pullup-supply = <&battery_reg>;*/
						force_bus_start = <CAMERA_I2C_MUX_BUS(0)>;
						vcc_lp = "vcc";
						i2c@0 {
							reg = <0>; // line 4 of the I2C switch
							i2c-mux,deselect-on-exit;
							#address-cells = <1>;
							#size-cells = <0>;

							g2m1_3: g2m3@6D {
								status = "okay";
								reg = <0x6D>;
								compatible = "orbbec,g300";
								use_sensor_mode_id = "true";
								vcc-supply = <&vdd_1v8_ls>;
								cam-type = "IR_R";
								dser-link-port = "b";
								st-vc = <3>;
								vc-id = <0>;
								orbbec_cam_num = <1>;
								nvidia,gmsl-dser-device = <&dser0>;
								pps-gpios = <&gpio_aon PPS_TRIGGER GPIO_ACTIVE_LOW>;
								ports {
									#address-cells = <1>;
									#size-cells = <0>;

									port@0 {
										reg = <0>;
										g2m1_3_out: endpoint {
											vc-id = <0>;
											port-index = <0>;
											bus-width = <4>;
											remote-endpoint = <&g300_csi_in7>;
										};
									};
								};
								mode0 {
									pixel_t = "grey_y8";
									num_lanes = "4";
									csi_pixel_bit_depth = "8";
									active_w = "1280";
									active_h = "720";
									tegra_sinterface = "serial_a";
									mclk_khz = "24000";
									pix_clk_hz = "750000000";  //4lane:750000000 ,2lane:375000000
									serdes_pix_clk_hz = "750000000";  //4lane:750000000 ,2lane:375000000 
									discontinuous_clk = "no";
									dpcm_enable = "false";
									cil_settletime = "0";
									line_length = "1280";
									mclk_multiplier = "15.625";
									embedded_metadata_height = "1";
									vc_id = "0";
								};
							};
							g2m1_2: g2m2@6C {
								status = "okay";
								reg = <0x6C>;
								compatible = "orbbec,g300";
								use_sensor_mode_id = "true";
								vcc-supply = <&vdd_1v8_ls>;
								cam-type = "IR_L";
								dser-link-port = "b";
								st-vc = <2>;
								vc-id = <1>;
								orbbec_cam_num = <1>;
								nvidia,gmsl-dser-device = <&dser0>;
								pps-gpios = <&gpio_aon PPS_TRIGGER GPIO_ACTIVE_LOW>;
								ports {
									#address-cells = <1>;
									#size-cells = <0>;

									port@0 {
										reg = <0>;
										g2m1_2_out: endpoint {
											vc-id = <1>;
											port-index = <0>;
											bus-width = <4>;
											remote-endpoint = <&g300_csi_in6>;
										};
									};
								};
								mode0 {
									pixel_t = "grey_y8";
									num_lanes = "4";
									csi_pixel_bit_depth = "8";
									active_w = "1280";
									active_h = "720";
									tegra_sinterface = "serial_a";
									mclk_khz = "24000";
									pix_clk_hz = "750000000";  //4lane:750000000 ,2lane:375000000
									serdes_pix_clk_hz = "750000000";  //4lane:750000000 ,2lane:375000000 
									discontinuous_clk = "no";
									dpcm_enable = "false";
									cil_settletime = "0";
									line_length = "1280";
									mclk_multiplier = "15.625";
									embedded_metadata_height = "1";
									vc_id = "1";
								};
							};
							g2m1_1: g2m1@6B {
								status = "okay";
								reg = <0x6B>;
								compatible = "orbbec,g300";
								use_sensor_mode_id = "true";
								vcc-supply = <&vdd_1v8_ls>;
								cam-type = "RGB";
								dser-link-port = "b";
								st-vc = <1>;
								vc-id = <2>;
								orbbec_cam_num = <1>;
								nvidia,gmsl-dser-device = <&dser0>;
								pps-gpios = <&gpio_aon PPS_TRIGGER GPIO_ACTIVE_LOW>;
								ports {
									#address-cells = <1>;
									#size-cells = <0>;

									port@0 {
										reg = <0>;
										g2m1_1_out: endpoint {
											vc-id = <2>;
											port-index = <0>;
											bus-width = <4>;
											remote-endpoint = <&g300_csi_in5>;
										};
									};
								};
								mode0 {
									pixel_t = "yuv_yvyu16";
									num_lanes = "4";
									csi_pixel_bit_depth = "16";
									active_w = "1280";
									active_h = "720";
									tegra_sinterface = "serial_a";
									mclk_khz = "24000";
									pix_clk_hz = "375000000";  //4lane:375000000,2lane:187500000
									serdes_pix_clk_hz = "375000000";  //4lane:375000000,2lane:187500000 
									discontinuous_clk = "no";
									dpcm_enable = "false";
									cil_settletime = "0";
									line_length = "1280";
									mclk_multiplier = "15.625";
									embedded_metadata_height = "1";
									vc_id = "2";
								};
							};
							g2m1_0: g2m0@6A {
								status = "okay";
								reg = <0x6A>;
								compatible = "orbbec,g300";
								use_sensor_mode_id = "true";
								vcc-supply = <&vdd_1v8_ls>;
								cam-type = "Depth";
								dser-link-port = "b";
								st-vc = <0>;
								vc-id = <3>;
								orbbec_cam_num = <1>;
								nvidia,gmsl-dser-device = <&dser0>;
								pps-gpios = <&gpio_aon PPS_TRIGGER GPIO_ACTIVE_LOW>;
								ports {
									#address-cells = <1>;
									#size-cells = <0>;

									port@0 {
										reg = <0>;
										g2m1_0_out: endpoint {
											vc-id = <3>;
											port-index = <0>;
											bus-width = <4>;
											remote-endpoint = <&g300_csi_in4>;
										};
									};
								};
								mode0 {
									pixel_t = "yuv_yvyu16";
									num_lanes = "4";
									csi_pixel_bit_depth = "16";
									active_w = "1280";
									active_h = "720";
									tegra_sinterface = "serial_a";
									mclk_khz = "24000";
									pix_clk_hz = "375000000";  //4lane:375000000,2lane:187500000
									serdes_pix_clk_hz = "375000000";  //4lane:375000000,2lane:187500000 
									discontinuous_clk = "no";
									dpcm_enable = "false";
									cil_settletime = "0";
									line_length = "1280";
									mclk_multiplier = "15.625";
									embedded_metadata_height = "1";
									vc_id = "2";
								};
							};

							/* IR_R */
							g2m0_3: g2m3@69 {
								status = "okay";
								reg = <0x69>;
								compatible = "orbbec,g300";
								use_sensor_mode_id = "true";
								vcc-supply = <&vdd_1v8_ls>;
								cam-type = "IR_R";
								dser-link-port = "a";
								st-vc = <3>;
								vc-id = <3>;
								orbbec_cam_num = <0>;
								nvidia,gmsl-dser-device = <&dser0>;
								pps-gpios = <&gpio_aon PPS_TRIGGER GPIO_ACTIVE_LOW>;
								ports {
									#address-cells = <1>;
									#size-cells = <0>;

									port@0 {
										reg = <0>;
										g2m0_3_out: endpoint {
											vc-id = <3>;
											port-index = <0>; //0
											bus-width = <4>;
											remote-endpoint = <&g300_csi_in3>;
										};
									};
								};
								mode0 {
									pixel_t = "grey_y8";
									num_lanes = "4";
									csi_pixel_bit_depth = "8";
									active_w = "1280";
									active_h = "720";
									tegra_sinterface = "serial_a";
									mclk_khz = "24000";
									pix_clk_hz = "750000000";  //4lane:750000000 ,2lane:375000000
									serdes_pix_clk_hz = "750000000";  //4lane:750000000 ,2lane:375000000 
									discontinuous_clk = "no";
									dpcm_enable = "false";
									cil_settletime = "0";
									line_length = "1280";
									mclk_multiplier = "15.625";
									embedded_metadata_height = "1";
									vc_id = "3";
								};
							};
							/* IR_L */
							g2m0_2: g2m2@68 {
								status = "okay";
								reg = <0x68>;
								compatible = "orbbec,g300";
								use_sensor_mode_id = "true";
								vcc-supply = <&vdd_1v8_ls>;
								cam-type = "IR_L";
								dser-link-port = "a";
								st-vc = <2>;
								vc-id = <2>;
								orbbec_cam_num = <0>;
								nvidia,gmsl-dser-device = <&dser0>;
								pps-gpios = <&gpio_aon PPS_TRIGGER GPIO_ACTIVE_LOW>;
								ports {
									#address-cells = <1>;
									#size-cells = <0>;

									port@0 {
										reg = <0>;
										g2m0_2_out: endpoint {
											vc-id = <2>;
											port-index = <0>;
											bus-width = <4>;
											remote-endpoint = <&g300_csi_in2>;
										};
									};
								};
								mode0 {
									pixel_t = "grey_y8";
									num_lanes = "4";
									csi_pixel_bit_depth = "8";
									active_w = "1280";
									active_h = "720";
									tegra_sinterface = "serial_a";
									mclk_khz = "24000";
									pix_clk_hz = "750000000";  //4lane:750000000 ,2lane:375000000
									serdes_pix_clk_hz = "750000000";  //4lane:750000000 ,2lane:375000000 
									discontinuous_clk = "no";
									dpcm_enable = "false";
									cil_settletime = "0";
									line_length = "1280";
									mclk_multiplier = "15.625";
									embedded_metadata_height = "1";
									vc_id = "2";
								};
							};
							/* RGB */
							g2m0_1: g2m1@67 {
								status = "okay";
								reg = <0x67>;
								compatible = "orbbec,g300";
								use_sensor_mode_id = "true";
								vcc-supply = <&vdd_1v8_ls>;
								cam-type = "RGB";
								dser-link-port = "a";
								st-vc = <1>;
								vc-id = <1>;
								orbbec_cam_num = <0>;
								nvidia,gmsl-dser-device = <&dser0>;
								pps-gpios = <&gpio_aon PPS_TRIGGER GPIO_ACTIVE_LOW>;
								ports {
									#address-cells = <1>;
									#size-cells = <0>;

									port@0 {
										reg = <0>;
										g2m0_1_out: endpoint {
											vc-id = <1>;
											port-index = <0>;
											bus-width = <4>;
											remote-endpoint = <&g300_csi_in1>;
										};
									};
								};
								mode0 {
									pixel_t = "yuv_yvyu16";
									num_lanes = "4";
									csi_pixel_bit_depth = "16";
									active_w = "1280";
									active_h = "720";
									tegra_sinterface = "serial_a";
									mclk_khz = "24000";
									pix_clk_hz = "375000000";  //4lane:375000000,2lane:187500000
									serdes_pix_clk_hz = "375000000";  //4lane:375000000,2lane:187500000 
									discontinuous_clk = "no";
									dpcm_enable = "false";
									cil_settletime = "0";
									line_length = "1280";
									mclk_multiplier = "15.625";
									embedded_metadata_height = "1"; 
									vc_id = "1";
								};
							};
							/* Depth */
							g2m0_0: g2m0@66 {
								status = "okay";
								def-addr = <0x66>;
								reg = <0x66>;
								compatible = "orbbec,g300";
								use_sensor_mode_id = "true";
								vcc-supply = <&vdd_1v8_ls>;
								cam-type = "Depth";
								dser-link-port = "a";
								st-vc = <0>;   				/**< Default sensor virtual channel. */
								vc-id = <0>;				/**< Destination virtual channel (user-defined). */
								orbbec_cam_num = <0>;
								nvidia,gmsl-dser-device = <&dser0>;
								pps-gpios = <&gpio_aon PPS_TRIGGER GPIO_ACTIVE_LOW>;
								ports {
									#address-cells = <1>;
									#size-cells = <0>;

									port@0 {
										reg = <0>;
										g2m0_0_out: endpoint {
											vc-id = <0>;
											port-index = <0>;
											bus-width = <4>;
											remote-endpoint = <&g300_csi_in0>;
										};
									};
								};
								mode0 {
									pixel_t = "yuv_yvyu16";
									num_lanes = "4";
									csi_pixel_bit_depth = "16";
									active_w = "1280";
									active_h = "720";
									tegra_sinterface = "serial_a";
									mclk_khz = "24000";
									pix_clk_hz = "375000000";  //4lane:375000000,2lane:187500000
									serdes_pix_clk_hz = "375000000";  //4lane:375000000,2lane:187500000 
									discontinuous_clk = "no";
									dpcm_enable = "false";
									cil_settletime = "0";
									line_length = "1280";
									mclk_multiplier = "15.625";
									embedded_metadata_height = "1"; 
									vc_id = "0";
								};
							};

							dser0: max9296@48 {
								status = "okay";
								reg = <0x48>; //0x90>>1
								compatible = "maxim,obc_max9296";
								index = <0>;
								csi-mode = "2x4"; //2*4lane
								seri-addr = <0x50>; //serializer start address, LinkA serializer i2c address,LINK B + 1
								proxy-addr = <0x1a>; //camera proxy address, LinkA g300 i2c address,LINK B + 1,LINK C + 2,LINK D + 3
								real-addr = <0x66>; //camera real address
								reset-gpios = <&gpio CAM0_PWDN GPIO_ACTIVE_HIGH>;
								fsync_mfp_index = <6>;
								pps_mfp_index = <9>;
								is-fg96-8ch-v2.1;
							};
						};
						i2c@1 {
							status = "okay";
							reg = <1>; // line 4 of the I2C switch
							i2c-mux,deselect-on-exit;
							#address-cells = <1>;
							#size-cells = <0>;

							g2m3_3: g2m3@6D {
								status = "okay";
								reg = <0x6D>;
								compatible = "orbbec,g300";
								use_sensor_mode_id = "true";
								vcc-supply = <&vdd_1v8_ls>;
								cam-type = "IR_R";
								dser-link-port = "b";
								st-vc = <3>;
								vc-id = <0>;
								orbbec_cam_num = <3>;
								nvidia,gmsl-dser-device = <&dser1>;
								pps-gpios = <&gpio_aon PPS_TRIGGER GPIO_ACTIVE_LOW>;
								ports {
									#address-cells = <1>;
									#size-cells = <0>;

									port@0 {
										reg = <0>;
										g2m3_3_out: endpoint {
											vc-id = <0>;
											port-index = <2>;
											bus-width = <4>;
											remote-endpoint = <&g300_csi_in15>;
										};
									};
								};
								mode0 {
									pixel_t = "grey_y8";
									num_lanes = "4";
									csi_pixel_bit_depth = "8";
									active_w = "1280";
									active_h = "720";
									tegra_sinterface = "serial_c";
									mclk_khz = "24000";
									pix_clk_hz = "750000000";  //4lane:750000000 ,2lane:375000000
									serdes_pix_clk_hz = "750000000";  //4lane:750000000 ,2lane:375000000 
									discontinuous_clk = "no";
									dpcm_enable = "false";
									cil_settletime = "0";
									line_length = "1280";
									mclk_multiplier = "15.625";
									embedded_metadata_height = "1";
									vc_id = "0";
								};
							};
							g2m3_2: g2m2@6C {
								status = "okay";
								reg = <0x6C>;
								compatible = "orbbec,g300";
								use_sensor_mode_id = "true";
								vcc-supply = <&vdd_1v8_ls>;
								cam-type = "IR_L";
								dser-link-port = "b";
								st-vc = <2>;
								vc-id = <1>;
								orbbec_cam_num = <3>;
								nvidia,gmsl-dser-device = <&dser1>;
								pps-gpios = <&gpio_aon PPS_TRIGGER GPIO_ACTIVE_LOW>;
								ports {
									#address-cells = <1>;
									#size-cells = <0>;

									port@0 {
										reg = <0>;
										g2m3_2_out: endpoint {
											vc-id = <1>;
											port-index = <2>;
											bus-width = <4>;
											remote-endpoint = <&g300_csi_in14>;
										};
									};
								};
								mode0 {
									pixel_t = "grey_y8";
									num_lanes = "4";
									csi_pixel_bit_depth = "8";
									active_w = "1280";
									active_h = "720";
									tegra_sinterface = "serial_c";
									mclk_khz = "24000";
									pix_clk_hz = "750000000";  //4lane:750000000 ,2lane:375000000
									serdes_pix_clk_hz = "750000000";  //4lane:750000000 ,2lane:375000000 
									discontinuous_clk = "no";
									dpcm_enable = "false";
									cil_settletime = "0";
									line_length = "1280";
									mclk_multiplier = "15.625";
									embedded_metadata_height = "1";
									vc_id = "1";
								};
							};
							g2m3_1: g2m1@6B {
								status = "okay";
								reg = <0x6B>;
								compatible = "orbbec,g300";
								use_sensor_mode_id = "true";
								vcc-supply = <&vdd_1v8_ls>;
								cam-type = "RGB";
								dser-link-port = "b";
								st-vc = <1>;
								vc-id = <2>;
								orbbec_cam_num = <3>;
								nvidia,gmsl-dser-device = <&dser1>;
								pps-gpios = <&gpio_aon PPS_TRIGGER GPIO_ACTIVE_LOW>;
								ports {
									#address-cells = <1>;
									#size-cells = <0>;

									port@0 {
										reg = <0>;
										g2m3_1_out: endpoint {
											vc-id = <2>;
											port-index = <2>;
											bus-width = <4>;
											remote-endpoint = <&g300_csi_in13>;
										};
									};
								};
								mode0 {
									pixel_t = "yuv_yvyu16";
									num_lanes = "4";
									csi_pixel_bit_depth = "16";
									active_w = "1280";
									active_h = "720";
									tegra_sinterface = "serial_c";
									mclk_khz = "24000";
									pix_clk_hz = "375000000";  //4lane:375000000,2lane:187500000
									serdes_pix_clk_hz = "375000000";  //4lane:375000000,2lane:187500000 
									discontinuous_clk = "no";
									dpcm_enable = "false";
									cil_settletime = "0";
									line_length = "1280";
									mclk_multiplier = "15.625";
									embedded_metadata_height = "1"; 
									vc_id = "2";
								};
							};
							g2m3_0: g2m0@6A {
								status = "okay";
								reg = <0x6A>;
								compatible = "orbbec,g300";
								use_sensor_mode_id = "true";
								vcc-supply = <&vdd_1v8_ls>;
								cam-type = "Depth";
								dser-link-port = "b";
								st-vc = <0>;
								vc-id = <3>;
								orbbec_cam_num = <3>;
								nvidia,gmsl-dser-device = <&dser1>;
								pps-gpios = <&gpio_aon PPS_TRIGGER GPIO_ACTIVE_LOW>;
								ports {
									#address-cells = <1>;
									#size-cells = <0>;

									port@0 {
										reg = <0>;
										g2m3_0_out: endpoint {
											vc-id = <3>;
											port-index = <2>;
											bus-width = <4>;
											remote-endpoint = <&g300_csi_in12>;
										};
									};
								};
								mode0 {
									pixel_t = "yuv_yvyu16";
									num_lanes = "4";
									csi_pixel_bit_depth = "16";
									active_w = "1280";
									active_h = "720";
									tegra_sinterface = "serial_c";
									mclk_khz = "24000";
									pix_clk_hz = "375000000";  //4lane:375000000,2lane:187500000
									serdes_pix_clk_hz = "375000000";  //4lane:375000000,2lane:187500000 
									discontinuous_clk = "no";
									dpcm_enable = "false";
									cil_settletime = "0";
									line_length = "1280";
									mclk_multiplier = "15.625";
									embedded_metadata_height = "1"; 
									vc_id = "3";
								};
							};

							g2m2_3: g2m3@69 {
								status = "okay";
								reg = <0x69>;
								compatible = "orbbec,g300";
								use_sensor_mode_id = "true";
								vcc-supply = <&vdd_1v8_ls>;
								cam-type = "IR_R";
								dser-link-port = "a";
								st-vc = <3>;
								vc-id = <3>;
								orbbec_cam_num = <2>;
								nvidia,gmsl-dser-device = <&dser1>;
								pps-gpios = <&gpio_aon PPS_TRIGGER GPIO_ACTIVE_LOW>;
								ports {
									#address-cells = <1>;
									#size-cells = <0>;

									port@0 {
										reg = <0>;
										g2m2_3_out: endpoint {
											vc-id = <3>;
											port-index = <2>;
											bus-width = <4>;
											remote-endpoint = <&g300_csi_in11>;
										};
									};
								};
								mode0 {
									pixel_t = "grey_y8";
									num_lanes = "4";
									csi_pixel_bit_depth = "8";
									active_w = "1280";
									active_h = "720";
									tegra_sinterface = "serial_c";
									mclk_khz = "24000";
									pix_clk_hz = "750000000";  //4lane:750000000 ,2lane:375000000
									serdes_pix_clk_hz = "750000000";  //4lane:750000000 ,2lane:375000000 
									discontinuous_clk = "no";
									dpcm_enable = "false";
									cil_settletime = "0";
									line_length = "1280";
									mclk_multiplier = "15.625";
									embedded_metadata_height = "1";
									vc_id = "3";
								};
							};
							g2m2_2: g2m2@68 {
								status = "okay";
								reg = <0x68>;
								compatible = "orbbec,g300";
								use_sensor_mode_id = "true";
								vcc-supply = <&vdd_1v8_ls>;
								cam-type = "IR_L";
								dser-link-port = "a";
								st-vc = <2>;
								vc-id = <2>;
								orbbec_cam_num = <2>;
								nvidia,gmsl-dser-device = <&dser1>;
								pps-gpios = <&gpio_aon PPS_TRIGGER GPIO_ACTIVE_LOW>;
								ports {
									#address-cells = <1>;
									#size-cells = <0>;

									port@0 {
										reg = <0>;
										g2m2_2_out: endpoint {
											vc-id = <2>;
											port-index = <2>;
											bus-width = <4>;
											remote-endpoint = <&g300_csi_in10>;
										};
									};
								};
								mode0 {
									pixel_t = "grey_y8";
									num_lanes = "4";
									csi_pixel_bit_depth = "8";
									active_w = "1280";
									active_h = "720";
									tegra_sinterface = "serial_c";
									mclk_khz = "24000";
									pix_clk_hz = "750000000";  //4lane:750000000 ,2lane:375000000
									serdes_pix_clk_hz = "750000000";  //4lane:750000000 ,2lane:375000000 
									discontinuous_clk = "no";
									dpcm_enable = "false";
									cil_settletime = "0";
									line_length = "1280";
									mclk_multiplier = "15.625";
									embedded_metadata_height = "1";
									vc_id = "2";
								};
							};
							g2m2_1: g2m1@67 {
								status = "okay";
								reg = <0x67>;
								compatible = "orbbec,g300";
								use_sensor_mode_id = "true";
								vcc-supply = <&vdd_1v8_ls>;
								cam-type = "RGB";
								dser-link-port = "a";
								st-vc = <1>;
								vc-id = <1>;
								orbbec_cam_num = <2>;
								nvidia,gmsl-dser-device = <&dser1>;
								pps-gpios = <&gpio_aon PPS_TRIGGER GPIO_ACTIVE_LOW>;
								ports {
									#address-cells = <1>;
									#size-cells = <0>;

									port@0 {
										reg = <0>;
										g2m2_1_out: endpoint {
											vc-id = <1>;
											port-index = <2>;
											bus-width = <4>;
											remote-endpoint = <&g300_csi_in9>;
										};
									};
								};
								mode0 {
									pixel_t = "yuv_yvyu16";
									num_lanes = "4";
									csi_pixel_bit_depth = "16";
									active_w = "1280";
									active_h = "720";
									tegra_sinterface = "serial_c";
									mclk_khz = "24000";
									pix_clk_hz = "375000000";  //4lane:375000000,2lane:187500000
									serdes_pix_clk_hz = "375000000";  //4lane:375000000,2lane:187500000 
									discontinuous_clk = "no";
									dpcm_enable = "false";
									cil_settletime = "0";
									line_length = "1280";
									mclk_multiplier = "15.625";
									embedded_metadata_height = "1";
									vc_id = "1";
								};
							};
							g2m2_0: g2m0@66 {
								status = "okay";
								reg = <0x66>;
								compatible = "orbbec,g300";
								use_sensor_mode_id = "true";
								vcc-supply = <&vdd_1v8_ls>;
								cam-type = "Depth";
								dser-link-port = "a";
								st-vc = <0>;   				/**< Default sensor virtual channel. */
								vc-id = <0>;				/**< Destination virtual channel (user-defined). */
								orbbec_cam_num = <2>;
								nvidia,gmsl-dser-device = <&dser1>;
								pps-gpios = <&gpio_aon PPS_TRIGGER GPIO_ACTIVE_LOW>;
								ports {
									#address-cells = <1>;
									#size-cells = <0>;

									port@0 {
										reg = <0>;
										g2m2_0_out: endpoint {
											vc-id = <0>;
											port-index = <2>;
											bus-width = <4>;
											remote-endpoint = <&g300_csi_in8>;
										};
									};
								};
								mode0 {
									pixel_t = "yuv_yvyu16";
									num_lanes = "4";
									csi_pixel_bit_depth = "16";
									active_w = "1280";
									active_h = "720";
									tegra_sinterface = "serial_c";
									mclk_khz = "24000";
									pix_clk_hz = "375000000";  //4lane:375000000,2lane:187500000
									serdes_pix_clk_hz = "375000000";  //4lane:375000000,2lane:187500000 
									discontinuous_clk = "no";
									dpcm_enable = "false";
									cil_settletime = "0";
									line_length = "1280";
									mclk_multiplier = "15.625";
									embedded_metadata_height = "1";
									vc_id = "0";
								};
							};

							dser1: max9296@48 {
								status = "okay";
								reg = <0x48>; //0x90>>1
								compatible = "maxim,obc_max9296";
								index = <1>;
								csi-mode = "2x4"; //2*4lane
								seri-addr = <0x50>; //serializer start address, LinkA serializer i2c address,LINK B + 1
								proxy-addr = <0x1a>; //camera proxy address, LinkA g300 i2c address,LINK B + 1,LINK C + 2,LINK D + 3
								real-addr = <0x66>;  //camera real address
								reset-gpios = <&gpio CAM1_PWDN GPIO_ACTIVE_HIGH>;
								fsync_mfp_index = <6>;
								pps_mfp_index = <9>;
								is-fg96-8ch-v2.1;
							};
						};

						i2c@2 {
							reg = <2>; // line 4 of the I2C switch
							i2c-mux,deselect-on-exit;
							#address-cells = <1>;
							#size-cells = <0>;

							g2m5_3: g2m3@6D {
								status = "okay";
								reg = <0x6D>;
								compatible = "orbbec,g300";
								use_sensor_mode_id = "true";
								vcc-supply = <&vdd_1v8_ls>;
								cam-type = "IR_R";
								dser-link-port = "b";
								st-vc = <3>;
								vc-id = <0>;
								orbbec_cam_num = <5>;
								nvidia,gmsl-dser-device = <&dser2>;
								pps-gpios = <&gpio_aon PPS_TRIGGER GPIO_ACTIVE_LOW>;
								ports {
									#address-cells = <1>;
									#size-cells = <0>;

									port@0 {
										reg = <0>;
										g2m5_3_out: endpoint {
											vc-id = <0>;
											port-index = <4>;
											bus-width = <4>;
											remote-endpoint = <&g300_csi_in23>;
										};
									};
								};
								mode0 {
									pixel_t = "grey_y8";
									num_lanes = "4";
									csi_pixel_bit_depth = "8";
									active_w = "1280";
									active_h = "720";
									tegra_sinterface = "serial_a";
									mclk_khz = "24000";
									pix_clk_hz = "750000000";  //4lane:750000000 ,2lane:375000000
									serdes_pix_clk_hz = "750000000";  //4lane:750000000 ,2lane:375000000 
									discontinuous_clk = "no";
									dpcm_enable = "false";
									cil_settletime = "0";
									line_length = "1280";
									mclk_multiplier = "15.625";
									embedded_metadata_height = "1";
									vc_id = "0";
								};
							};
							g2m5_2: g2m2@6C {
								status = "okay";
								reg = <0x6C>;
								compatible = "orbbec,g300";
								use_sensor_mode_id = "true";
								vcc-supply = <&vdd_1v8_ls>;
								cam-type = "IR_L";
								dser-link-port = "b";
								st-vc = <2>;
								vc-id = <1>;
								orbbec_cam_num = <5>;
								nvidia,gmsl-dser-device = <&dser2>;
								pps-gpios = <&gpio_aon PPS_TRIGGER GPIO_ACTIVE_LOW>;
								ports {
									#address-cells = <1>;
									#size-cells = <0>;

									port@0 {
										reg = <0>;
										g2m5_2_out: endpoint {
											vc-id = <1>;
											port-index = <4>;
											bus-width = <4>;
											remote-endpoint = <&g300_csi_in22>;
										};
									};
								};
								mode0 {
									pixel_t = "grey_y8";
									num_lanes = "4";
									csi_pixel_bit_depth = "8";
									active_w = "1280";
									active_h = "720";
									tegra_sinterface = "serial_a";
									mclk_khz = "24000";
									pix_clk_hz = "750000000";  //4lane:750000000 ,2lane:375000000
									serdes_pix_clk_hz = "750000000";  //4lane:750000000 ,2lane:375000000 
									discontinuous_clk = "no";
									dpcm_enable = "false";
									cil_settletime = "0";
									line_length = "1280";
									mclk_multiplier = "15.625";
									embedded_metadata_height = "1";
									vc_id = "1";
								};
							};
							g2m5_1: g2m1@6B {
								status = "okay";
								reg = <0x6B>;
								compatible = "orbbec,g300";
								use_sensor_mode_id = "true";
								vcc-supply = <&vdd_1v8_ls>;
								cam-type = "RGB";
								dser-link-port = "b";
								st-vc = <1>;
								vc-id = <2>;
								orbbec_cam_num = <5>;
								nvidia,gmsl-dser-device = <&dser2>;
								pps-gpios = <&gpio_aon PPS_TRIGGER GPIO_ACTIVE_LOW>;
								ports {
									#address-cells = <1>;
									#size-cells = <0>;

									port@0 {
										reg = <0>;
										g2m5_1_out: endpoint {
											vc-id = <2>;
											port-index = <4>;
											bus-width = <4>;
											remote-endpoint = <&g300_csi_in21>;
										};
									};
								};
								mode0 {
									pixel_t = "yuv_yvyu16";
									num_lanes = "4";
									csi_pixel_bit_depth = "16";
									active_w = "1280";
									active_h = "720";
									tegra_sinterface = "serial_a";
									mclk_khz = "24000";
									pix_clk_hz = "375000000";  //4lane:375000000,2lane:187500000
									serdes_pix_clk_hz = "375000000";  //4lane:375000000,2lane:187500000 
									discontinuous_clk = "no";
									dpcm_enable = "false";
									cil_settletime = "0";
									line_length = "1280";
									mclk_multiplier = "15.625";
									embedded_metadata_height = "1";
									vc_id = "2";
								};
							};
							g2m5_0: g2m0@6A {
								status = "okay";
								reg = <0x6A>;
								compatible = "orbbec,g300";
								use_sensor_mode_id = "true";
								vcc-supply = <&vdd_1v8_ls>;
								cam-type = "Depth";
								dser-link-port = "b";
								st-vc = <0>;
								vc-id = <3>;
								orbbec_cam_num = <5>;
								nvidia,gmsl-dser-device = <&dser2>;
								pps-gpios = <&gpio_aon PPS_TRIGGER GPIO_ACTIVE_LOW>;
								ports {
									#address-cells = <1>;
									#size-cells = <0>;

									port@0 {
										reg = <0>;
										g2m5_0_out: endpoint {
											vc-id = <3>;
											port-index = <4>;
											bus-width = <4>;
											remote-endpoint = <&g300_csi_in20>;
										};
									};
								};
								mode0 {
									pixel_t = "yuv_yvyu16";
									num_lanes = "4";
									csi_pixel_bit_depth = "16";
									active_w = "1280";
									active_h = "720";
									tegra_sinterface = "serial_a";
									mclk_khz = "24000";
									pix_clk_hz = "375000000";  //4lane:375000000,2lane:187500000
									serdes_pix_clk_hz = "375000000";  //4lane:375000000,2lane:187500000 
									discontinuous_clk = "no";
									dpcm_enable = "false";
									cil_settletime = "0";
									line_length = "1280";
									mclk_multiplier = "15.625";
									embedded_metadata_height = "1";
									vc_id = "3";
								};
							};
							
							/* IR_R */
							g2m4_3: g2m3@69 {
								status = "okay";
								reg = <0x69>;
								compatible = "orbbec,g300";
								use_sensor_mode_id = "true";
								vcc-supply = <&vdd_1v8_ls>;
								cam-type = "IR_R";
								dser-link-port = "a";
								st-vc = <3>;
								vc-id = <3>;
								orbbec_cam_num = <4>;
								nvidia,gmsl-dser-device = <&dser2>;
								pps-gpios = <&gpio_aon PPS_TRIGGER GPIO_ACTIVE_LOW>;
								ports {
									#address-cells = <1>;
									#size-cells = <0>;

									port@0 {
										reg = <0>;
										g2m4_3_out: endpoint {
											vc-id = <3>;
											port-index = <4>; //0
											bus-width = <4>;
											remote-endpoint = <&g300_csi_in19>;
										};
									};
								};
								mode0 {
									pixel_t = "grey_y8";
									num_lanes = "4";
									csi_pixel_bit_depth = "8";
									active_w = "1280";
									active_h = "720";
									tegra_sinterface = "serial_a";
									mclk_khz = "24000";
									pix_clk_hz = "750000000";  //4lane:750000000 ,2lane:375000000
									serdes_pix_clk_hz = "750000000";  //4lane:750000000 ,2lane:375000000 
									discontinuous_clk = "no";
									dpcm_enable = "false";
									cil_settletime = "0";
									line_length = "1280";
									mclk_multiplier = "15.625";
									embedded_metadata_height = "1";
									vc_id = "3";
								};
							};
							/* IR_L */
							g2m4_2: g2m2@68 {
								status = "okay";
								reg = <0x68>;
								compatible = "orbbec,g300";
								use_sensor_mode_id = "true";
								vcc-supply = <&vdd_1v8_ls>;
								cam-type = "IR_L";
								dser-link-port = "a";
								st-vc = <2>;
								vc-id = <2>;
								orbbec_cam_num = <4>;
								nvidia,gmsl-dser-device = <&dser2>;
								pps-gpios = <&gpio_aon PPS_TRIGGER GPIO_ACTIVE_LOW>;
								ports {
									#address-cells = <1>;
									#size-cells = <0>;

									port@0 {
										reg = <0>;
										g2m4_2_out: endpoint {
											vc-id = <2>;
											port-index = <4>;
											bus-width = <4>;
											remote-endpoint = <&g300_csi_in18>;
										};
									};
								};
								mode0 {
									pixel_t = "grey_y8";
									num_lanes = "4";
									csi_pixel_bit_depth = "8";
									active_w = "1280";
									active_h = "720";
									tegra_sinterface = "serial_a";
									mclk_khz = "24000";
									pix_clk_hz = "750000000";  //4lane:750000000 ,2lane:375000000
									serdes_pix_clk_hz = "750000000";  //4lane:750000000 ,2lane:375000000 
									discontinuous_clk = "no";
									dpcm_enable = "false";
									cil_settletime = "0";
									line_length = "1280";
									mclk_multiplier = "15.625";
									embedded_metadata_height = "1";
									vc_id = "2";
								};
							};
							/* RGB */
							g2m4_1: g2m1@67 {
								status = "okay";
								reg = <0x67>;
								compatible = "orbbec,g300";
								use_sensor_mode_id = "true";
								vcc-supply = <&vdd_1v8_ls>;
								cam-type = "RGB";
								dser-link-port = "a";
								st-vc = <1>;
								vc-id = <1>;
								orbbec_cam_num = <4>;
								nvidia,gmsl-dser-device = <&dser2>;
								pps-gpios = <&gpio_aon PPS_TRIGGER GPIO_ACTIVE_LOW>;
								ports {
									#address-cells = <1>;
									#size-cells = <0>;

									port@0 {
										reg = <0>;
										g2m4_1_out: endpoint {
											vc-id = <1>;
											port-index = <4>;
											bus-width = <4>;
											remote-endpoint = <&g300_csi_in17>;
										};
									};
								};
								mode0 {
									pixel_t = "yuv_yvyu16";
									num_lanes = "4";
									csi_pixel_bit_depth = "16";
									active_w = "1280";
									active_h = "720";
									tegra_sinterface = "serial_a";
									mclk_khz = "24000";
									pix_clk_hz = "375000000";  //4lane:375000000,2lane:187500000
									serdes_pix_clk_hz = "375000000";  //4lane:375000000,2lane:187500000 
									discontinuous_clk = "no";
									dpcm_enable = "false";
									cil_settletime = "0";
									line_length = "1280";
									mclk_multiplier = "15.625";
									embedded_metadata_height = "1"; 
									vc_id = "1";
								};
							};
							/* Depth */
							g2m4_0: g2m0@66 {
								status = "okay";
								reg = <0x66>;
								compatible = "orbbec,g300";
								use_sensor_mode_id = "true";
								vcc-supply = <&vdd_1v8_ls>;
								cam-type = "Depth";
								dser-link-port = "a";
								st-vc = <0>;   				/**< Default sensor virtual channel. */
								vc-id = <0>;				/**< Destination virtual channel (user-defined). */
								orbbec_cam_num = <4>;
								nvidia,gmsl-dser-device = <&dser2>;
								pps-gpios = <&gpio_aon PPS_TRIGGER GPIO_ACTIVE_LOW>;
								ports {
									#address-cells = <1>;
									#size-cells = <0>;

									port@0 {
										reg = <0>;
										g2m4_0_out: endpoint {
											vc-id = <0>;
											port-index = <4>;
											bus-width = <4>;
											remote-endpoint = <&g300_csi_in16>;
										};
									};
								};
								mode0 {
									pixel_t = "yuv_yvyu16";
									num_lanes = "4";
									csi_pixel_bit_depth = "16";
									active_w = "1280";
									active_h = "720";
									tegra_sinterface = "serial_a";
									mclk_khz = "24000";
									pix_clk_hz = "375000000";  //4lane:375000000,2lane:187500000
									serdes_pix_clk_hz = "375000000";  //4lane:375000000,2lane:187500000 
									discontinuous_clk = "no";
									dpcm_enable = "false";
									cil_settletime = "0";
									line_length = "1280";
									mclk_multiplier = "15.625";
									embedded_metadata_height = "1"; 
									vc_id = "0";
								};
							};

							dser2: max9296@48 {
								status = "okay";
								reg = <0x48>; //0x90>>1
								compatible = "maxim,obc_max9296";
								index = <2>;
								csi-mode = "2x4"; //2*4lane
								seri-addr = <0x50>;  //serializer start address, LinkA serializer i2c address,LINK B + 1
								proxy-addr = <0x1a>; //camera proxy address, LinkA g300 i2c address,LINK B + 1,LINK C + 2,LINK D + 3
								real-addr = <0x66>; //camera real address
								reset-gpios = <&gpio CAM2_PWDN GPIO_ACTIVE_HIGH>;
								fsync_mfp_index = <6>;
								pps_mfp_index = <9>;
								is-fg96-8ch-v2.1;
							};
						};
						i2c@3 {
							status = "okay";
							reg = <3>; // line 4 of the I2C switch
							i2c-mux,deselect-on-exit;
							#address-cells = <1>;
							#size-cells = <0>;

							g2m7_3: g2m3@6D {
								status = "okay";
								reg = <0x6D>;
								compatible = "orbbec,g300";
								use_sensor_mode_id = "true";
								vcc-supply = <&vdd_1v8_ls>;
								cam-type = "IR_R";
								dser-link-port = "b";
								st-vc = <3>;
								vc-id = <0>;
								orbbec_cam_num = <7>;
								nvidia,gmsl-dser-device = <&dser3>;
								pps-gpios = <&gpio_aon PPS_TRIGGER GPIO_ACTIVE_LOW>;
								ports {
									#address-cells = <1>;
									#size-cells = <0>;

									port@0 {
										reg = <0>;
										g2m7_3_out: endpoint {
											vc-id = <0>;
											port-index = <6>;
											bus-width = <4>;
											remote-endpoint = <&g300_csi_in31>;
										};
									};
								};
								mode0 {
									pixel_t = "grey_y8";
									num_lanes = "4";
									csi_pixel_bit_depth = "8";
									active_w = "1280";
									active_h = "720";
									tegra_sinterface = "serial_c";
									mclk_khz = "24000";
									pix_clk_hz = "750000000";  //4lane:750000000 ,2lane:375000000
									serdes_pix_clk_hz = "750000000";  //4lane:750000000 ,2lane:375000000 
									discontinuous_clk = "no";
									dpcm_enable = "false";
									cil_settletime = "0";
									line_length = "1280";
									mclk_multiplier = "15.625";
									embedded_metadata_height = "1";
									vc_id = "0";
								};
							};
							g2m7_2: g2m2@6C {
								status = "okay";
								reg = <0x6C>;
								compatible = "orbbec,g300";
								use_sensor_mode_id = "true";
								vcc-supply = <&vdd_1v8_ls>;
								cam-type = "IR_L";
								dser-link-port = "b";
								st-vc = <2>;
								vc-id = <1>;
								orbbec_cam_num = <7>;
								nvidia,gmsl-dser-device = <&dser3>;
								pps-gpios = <&gpio_aon PPS_TRIGGER GPIO_ACTIVE_LOW>;
								ports {
									#address-cells = <1>;
									#size-cells = <0>;

									port@0 {
										reg = <0>;
										g2m7_2_out: endpoint {
											vc-id = <1>;
											port-index = <6>;
											bus-width = <4>;
											remote-endpoint = <&g300_csi_in30>;
										};
									};
								};
								mode0 {
									pixel_t = "grey_y8";
									num_lanes = "4";
									csi_pixel_bit_depth = "8";
									active_w = "1280";
									active_h = "720";
									tegra_sinterface = "serial_c";
									mclk_khz = "24000";
									pix_clk_hz = "750000000";  //4lane:750000000 ,2lane:375000000
									serdes_pix_clk_hz = "750000000";  //4lane:750000000 ,2lane:375000000 
									discontinuous_clk = "no";
									dpcm_enable = "false";
									cil_settletime = "0";
									line_length = "1280";
									mclk_multiplier = "15.625";
									embedded_metadata_height = "1";
									vc_id = "1";
								};
							};
							g2m7_1: g2m1@6B {
								status = "okay";
								reg = <0x6B>;
								compatible = "orbbec,g300";
								use_sensor_mode_id = "true";
								vcc-supply = <&vdd_1v8_ls>;
								cam-type = "RGB";
								dser-link-port = "b";
								st-vc = <1>;
								vc-id = <2>;
								orbbec_cam_num = <7>;
								nvidia,gmsl-dser-device = <&dser3>;
								pps-gpios = <&gpio_aon PPS_TRIGGER GPIO_ACTIVE_LOW>;
								ports {
									#address-cells = <1>;
									#size-cells = <0>;

									port@0 {
										reg = <0>;
										g2m7_1_out: endpoint {
											vc-id = <2>;
											port-index = <6>;
											bus-width = <4>;
											remote-endpoint = <&g300_csi_in29>;
										};
									};
								};
								mode0 {
									pixel_t = "yuv_yvyu16";
									num_lanes = "4";
									csi_pixel_bit_depth = "16";
									active_w = "1280";
									active_h = "720";
									tegra_sinterface = "serial_c";
									mclk_khz = "24000";
									pix_clk_hz = "375000000";  //4lane:375000000,2lane:187500000
									serdes_pix_clk_hz = "375000000";  //4lane:375000000,2lane:187500000 
									discontinuous_clk = "no";
									dpcm_enable = "false";
									cil_settletime = "0";
									line_length = "1280";
									mclk_multiplier = "15.625";
									embedded_metadata_height = "1"; 
									vc_id = "2";
								};
							};
							g2m7_0: g2m0@6A {
								status = "okay";
								reg = <0x6A>;
								compatible = "orbbec,g300";
								use_sensor_mode_id = "true";
								vcc-supply = <&vdd_1v8_ls>;
								cam-type = "Depth";
								dser-link-port = "b";
								st-vc = <0>;
								vc-id = <3>;
								orbbec_cam_num = <7>;
								nvidia,gmsl-dser-device = <&dser3>;
								pps-gpios = <&gpio_aon PPS_TRIGGER GPIO_ACTIVE_LOW>;
								ports {
									#address-cells = <1>;
									#size-cells = <0>;

									port@0 {
										reg = <0>;
										g2m7_0_out: endpoint {
											vc-id = <3>;
											port-index = <6>;
											bus-width = <4>;
											remote-endpoint = <&g300_csi_in28>;
										};
									};
								};
								mode0 {
									pixel_t = "yuv_yvyu16";
									num_lanes = "4";
									csi_pixel_bit_depth = "16";
									active_w = "1280";
									active_h = "720";
									tegra_sinterface = "serial_c";
									mclk_khz = "24000";
									pix_clk_hz = "375000000";  //4lane:375000000,2lane:187500000
									serdes_pix_clk_hz = "375000000";  //4lane:375000000,2lane:187500000 
									discontinuous_clk = "no";
									dpcm_enable = "false";
									cil_settletime = "0";
									line_length = "1280";
									mclk_multiplier = "15.625";
									embedded_metadata_height = "1"; 
									vc_id = "3";
								};
							};
							
							g2m6_3: g2m3@69 {
								status = "okay";
								reg = <0x69>;
								compatible = "orbbec,g300";
								use_sensor_mode_id = "true";
								vcc-supply = <&vdd_1v8_ls>;
								cam-type = "IR_R";
								dser-link-port = "a";
								st-vc = <3>;
								vc-id = <3>;
								orbbec_cam_num = <6>;
								nvidia,gmsl-dser-device = <&dser3>;
								pps-gpios = <&gpio_aon PPS_TRIGGER GPIO_ACTIVE_LOW>;
								ports {
									#address-cells = <1>;
									#size-cells = <0>;

									port@0 {
										reg = <0>;
										g2m6_3_out: endpoint {
											vc-id = <3>;
											port-index = <6>;
											bus-width = <4>;
											remote-endpoint = <&g300_csi_in27>;
										};
									};
								};
								mode0 {
									pixel_t = "grey_y8";
									num_lanes = "4";
									csi_pixel_bit_depth = "8";
									active_w = "1280";
									active_h = "720";
									tegra_sinterface = "serial_c";
									mclk_khz = "24000";
									pix_clk_hz = "750000000";  //4lane:750000000 ,2lane:375000000
									serdes_pix_clk_hz = "750000000";  //4lane:750000000 ,2lane:375000000 
									discontinuous_clk = "no";
									dpcm_enable = "false";
									cil_settletime = "0";
									line_length = "1280";
									mclk_multiplier = "15.625";
									embedded_metadata_height = "1";
									vc_id = "3";
								};
							};
							g2m6_2: g2m2@68 {
								status = "okay";
								reg = <0x68>;
								compatible = "orbbec,g300";
								use_sensor_mode_id = "true";
								vcc-supply = <&vdd_1v8_ls>;
								cam-type = "IR_L";
								dser-link-port = "a";
								st-vc = <2>;
								vc-id = <2>;
								orbbec_cam_num = <6>;
								nvidia,gmsl-dser-device = <&dser3>;
								pps-gpios = <&gpio_aon PPS_TRIGGER GPIO_ACTIVE_LOW>;
								ports {
									#address-cells = <1>;
									#size-cells = <0>;

									port@0 {
										reg = <0>;
										g2m6_2_out: endpoint {
											vc-id = <2>;
											port-index = <6>;
											bus-width = <4>;
											remote-endpoint = <&g300_csi_in26>;
										};
									};
								};
								mode0 {
									pixel_t = "grey_y8";
									num_lanes = "4";
									csi_pixel_bit_depth = "8";
									active_w = "1280";
									active_h = "720";
									tegra_sinterface = "serial_c";
									mclk_khz = "24000";
									pix_clk_hz = "750000000";  //4lane:750000000 ,2lane:375000000
									serdes_pix_clk_hz = "750000000";  //4lane:750000000 ,2lane:375000000 
									discontinuous_clk = "no";
									dpcm_enable = "false";
									cil_settletime = "0";
									line_length = "1280";
									mclk_multiplier = "15.625";
									embedded_metadata_height = "1";
									vc_id = "2";
								};
							};
							g2m6_1: g2m1@67 {
								status = "okay";
								reg = <0x67>;
								compatible = "orbbec,g300";
								use_sensor_mode_id = "true";
								vcc-supply = <&vdd_1v8_ls>;
								cam-type = "RGB";
								dser-link-port = "a";
								st-vc = <1>;
								vc-id = <1>;
								orbbec_cam_num = <6>;
								nvidia,gmsl-dser-device = <&dser3>;
								pps-gpios = <&gpio_aon PPS_TRIGGER GPIO_ACTIVE_LOW>;
								ports {
									#address-cells = <1>;
									#size-cells = <0>;

									port@0 {
										reg = <0>;
										g2m6_1_out: endpoint {
											vc-id = <1>;
											port-index = <6>;
											bus-width = <4>;
											remote-endpoint = <&g300_csi_in25>;
										};
									};
								};
								mode0 {
									pixel_t = "yuv_yvyu16";
									num_lanes = "4";
									csi_pixel_bit_depth = "16";
									active_w = "1280";
									active_h = "720";
									tegra_sinterface = "serial_c";
									mclk_khz = "24000";
									pix_clk_hz = "375000000";  //4lane:375000000,2lane:187500000
									serdes_pix_clk_hz = "375000000";  //4lane:375000000,2lane:187500000 
									discontinuous_clk = "no";
									dpcm_enable = "false";
									cil_settletime = "0";
									line_length = "1280";
									mclk_multiplier = "15.625";
									embedded_metadata_height = "1";
									vc_id = "1";
								};
							};
							g2m6_0: g2m0@66 {
								status = "okay";
								reg = <0x66>;
								compatible = "orbbec,g300";
								use_sensor_mode_id = "true";
								vcc-supply = <&vdd_1v8_ls>;
								cam-type = "Depth";
								dser-link-port = "a";
								st-vc = <0>;   				/**< Default sensor virtual channel. */
								vc-id = <0>;				/**< Destination virtual channel (user-defined). */
								orbbec_cam_num = <6>;
								nvidia,gmsl-dser-device = <&dser3>;
								pps-gpios = <&gpio_aon PPS_TRIGGER GPIO_ACTIVE_LOW>;
								ports {
									#address-cells = <1>;
									#size-cells = <0>;

									port@0 {
										reg = <0>;
										g2m6_0_out: endpoint {
											vc-id = <0>;
											port-index = <6>;
											bus-width = <4>;
											remote-endpoint = <&g300_csi_in24>;
										};
									};
								};
								mode0 {
									pixel_t = "yuv_yvyu16";
									num_lanes = "4";
									csi_pixel_bit_depth = "16";
									active_w = "1280";
									active_h = "720";
									tegra_sinterface = "serial_c";
									mclk_khz = "24000";
									pix_clk_hz = "375000000";  //4lane:375000000,2lane:187500000
									serdes_pix_clk_hz = "375000000";  //4lane:375000000,2lane:187500000 
									discontinuous_clk = "no";
									dpcm_enable = "false";
									cil_settletime = "0";
									line_length = "1280";
									mclk_multiplier = "15.625";
									embedded_metadata_height = "1";
									vc_id = "0";
								};
							};

							dser3: max9296@48 {
								status = "okay";
								reg = <0x48>; //0x90>>1
								compatible = "maxim,obc_max9296";
								index = <3>;
								csi-mode = "2x4"; //2*4lane
								seri-addr = <0x50>; //serializer start address, LinkA serializer i2c address,LINK B + 1
								proxy-addr = <0x1a>; //camera proxy address, LinkA g300 i2c address,LINK B + 1,LINK C + 2,LINK D + 3
								real-addr = <0x66>;  //camera real address
								reset-gpios = <&gpio CAM3_PWDN GPIO_ACTIVE_HIGH>;
								fsync_mfp_index = <6>;
								pps_mfp_index = <9>;
								is-fg96-8ch-v2.1;
							};
						};
					};
				};
			};
		};
	};
};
